VERSION "0.0.02"

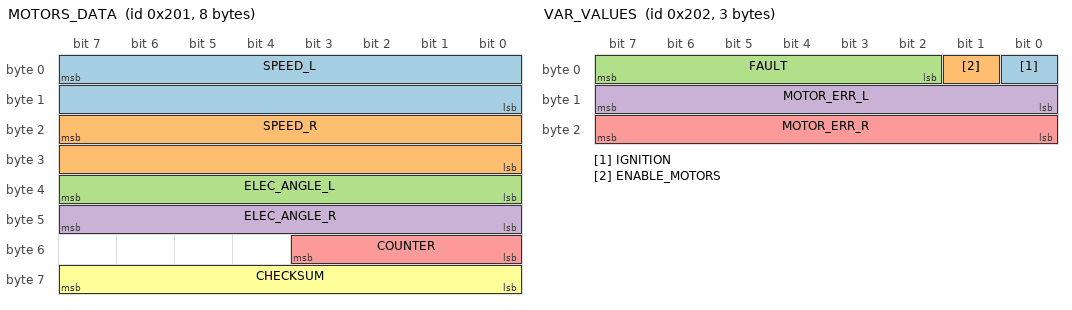
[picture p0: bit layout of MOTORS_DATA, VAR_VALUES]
BO_ 513 MOTORS_DATA: 8 XXX
  SG_ SPEED_L : 7|16@0- (1,0) [-1000|1000] "" XXX
  SG_ SPEED_R : 23|16@0- (1,0) [-1000|1000] "" XXX
  SG_ ELEC_ANGLE_L : 39|8@0+ (1,0) [0|0] "deprecated" XXX
  SG_ ELEC_ANGLE_R : 47|8@0+ (1,0) [0|0] "deprecated" XXX
  SG_ COUNTER : 51|4@0+ (1,0) [0|15] "" XXX
  SG_ CHECKSUM : 63|8@0+ (1,0) [0|255] "" XXX

BO_ 514 VAR_VALUES: 3 XXX
  SG_ IGNITION : 0|1@0+ (1,0) [0|1] "" XXX
  SG_ ENABLE_MOTORS : 1|1@0+ (1,0) [0|1] "" XXX
  SG_ FAULT : 7|6@0+ (1,0) [0|63] "" XXX
  SG_ MOTOR_ERR_L : 15|8@0+ (1,0) [0|255] "" XXX
  SG_ MOTOR_ERR_R : 23|8@0+ (1,0) [0|255] "" XXX

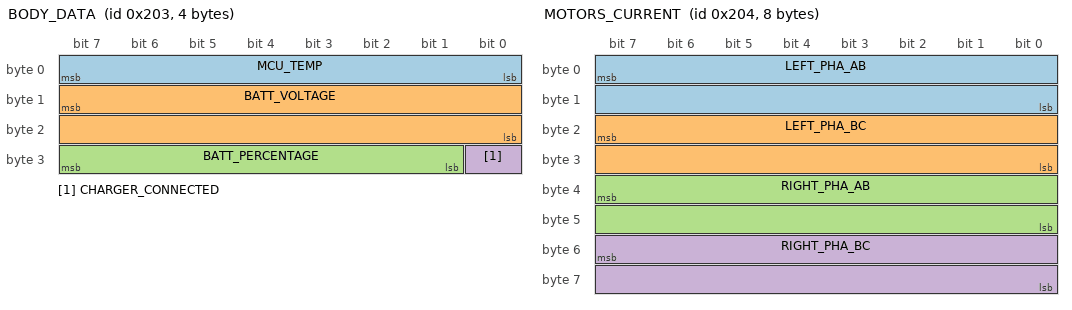
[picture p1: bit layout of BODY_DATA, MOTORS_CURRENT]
BO_ 515 BODY_DATA: 4 XXX
  SG_ MCU_TEMP : 7|8@0+ (0.1,0) [0|125] "" XXX
  SG_ BATT_VOLTAGE : 15|16@0+ (0.01,0) [0|60] "" XXX
  SG_ BATT_PERCENTAGE : 31|7@0+ (1,0) [0|100] "" XXX
  SG_ CHARGER_CONNECTED : 24|1@0+ (1,0) [0|1] "" XXX

BO_ 516 MOTORS_CURRENT: 8 XXX
  SG_ LEFT_PHA_AB : 7|16@0- (1,0) [-32768|32767] "" XXX
  SG_ LEFT_PHA_BC : 23|16@0- (1,0) [-32768|32767] "" XXX
  SG_ RIGHT_PHA_AB : 39|16@0- (1,0) [-32768|32767] "" XXX
  SG_ RIGHT_PHA_BC : 55|16@0- (1,0) [-32768|32767] "" XXX

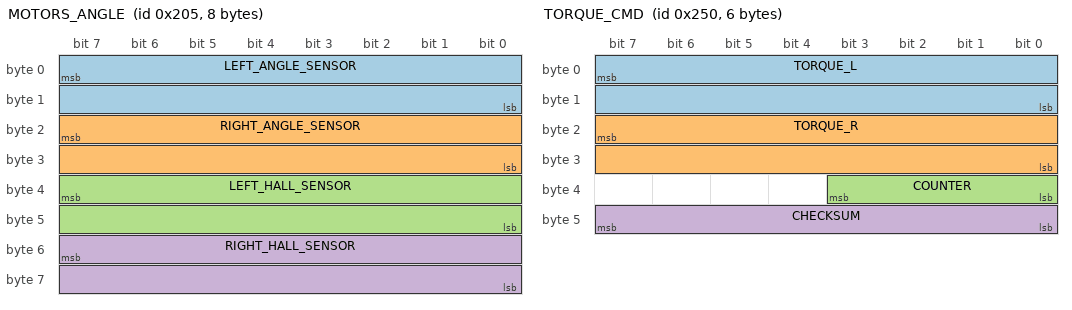
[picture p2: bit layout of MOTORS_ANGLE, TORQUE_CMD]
BO_ 517 MOTORS_ANGLE: 8 XXX
  SG_ LEFT_ANGLE_SENSOR : 7|16@0+ (1,0) [0|16384] "" XXX
  SG_ RIGHT_ANGLE_SENSOR : 23|16@0+ (1,0) [0|16384] "" XXX
  SG_ LEFT_HALL_SENSOR : 39|16@0+ (1,0) [0|360] "" XXX
  SG_ RIGHT_HALL_SENSOR : 55|16@0+ (1,0) [0|360] "" XXX

BO_ 592 TORQUE_CMD: 6 XXX
  SG_ TORQUE_L : 7|16@0- (1,0) [-1000|1000] "" XXX
  SG_ TORQUE_R : 23|16@0- (1,0) [-1000|1000] "" XXX
  SG_ COUNTER : 35|4@0+ (1,0) [0|15] "" XXX
  SG_ CHECKSUM : 47|8@0+ (1,0) [0|255] "" XXX

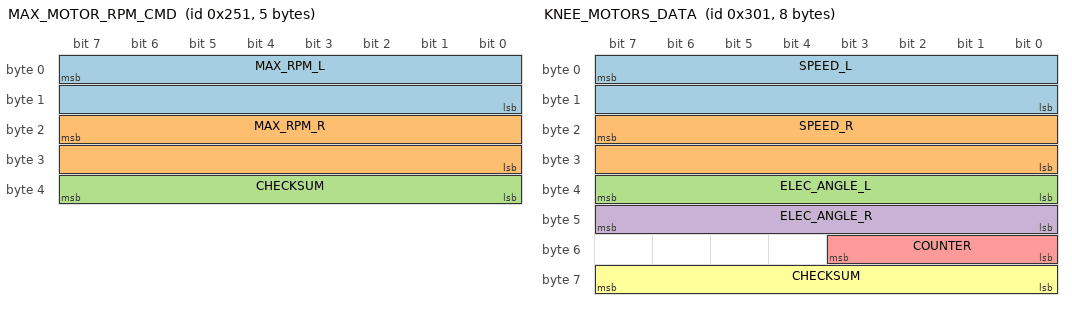
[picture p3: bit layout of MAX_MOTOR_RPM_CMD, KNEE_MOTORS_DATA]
BO_ 593 MAX_MOTOR_RPM_CMD: 5 XXX
  SG_ MAX_RPM_L : 7|16@0+ (1,0) [0|1000] "" XXX
  SG_ MAX_RPM_R : 23|16@0+ (1,0) [0|1000] "" XXX
  SG_ CHECKSUM : 39|8@0+ (1,0) [0|255] "" XXX

BO_ 769 KNEE_MOTORS_DATA: 8 XXX
  SG_ SPEED_L : 7|16@0- (1,0) [-1000|1000] "" XXX
  SG_ SPEED_R : 23|16@0- (1,0) [-1000|1000] "" XXX
  SG_ ELEC_ANGLE_L : 39|8@0+ (1,0) [0|0] "deprecated" XXX
  SG_ ELEC_ANGLE_R : 47|8@0+ (1,0) [0|0] "deprecated" XXX
  SG_ COUNTER : 51|4@0+ (1,0) [0|15] "" XXX
  SG_ CHECKSUM : 63|8@0+ (1,0) [0|255] "" XXX

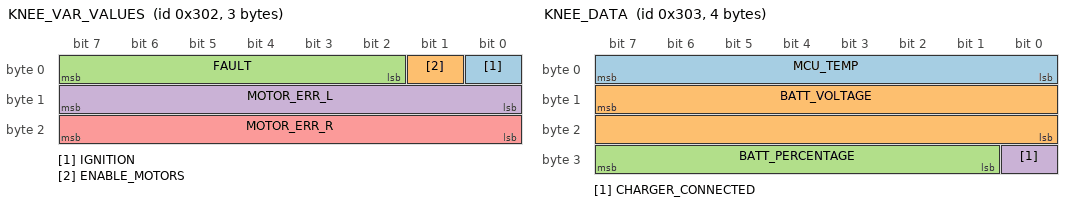
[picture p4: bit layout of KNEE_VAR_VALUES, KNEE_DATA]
BO_ 770 KNEE_VAR_VALUES: 3 XXX
  SG_ IGNITION : 0|1@0+ (1,0) [0|1] "" XXX
  SG_ ENABLE_MOTORS : 1|1@0+ (1,0) [0|1] "" XXX
  SG_ FAULT : 7|6@0+ (1,0) [0|63] "" XXX
  SG_ MOTOR_ERR_L : 15|8@0+ (1,0) [0|255] "" XXX
  SG_ MOTOR_ERR_R : 23|8@0+ (1,0) [0|255] "" XXX

BO_ 771 KNEE_DATA: 4 XXX
  SG_ MCU_TEMP : 7|8@0+ (0.1,0) [0|125] "" XXX
  SG_ BATT_VOLTAGE : 15|16@0+ (0.01,0) [0|60] "" XXX
  SG_ BATT_PERCENTAGE : 31|7@0+ (1,0) [0|100] "" XXX
  SG_ CHARGER_CONNECTED : 24|1@0+ (1,0) [0|1] "" XXX

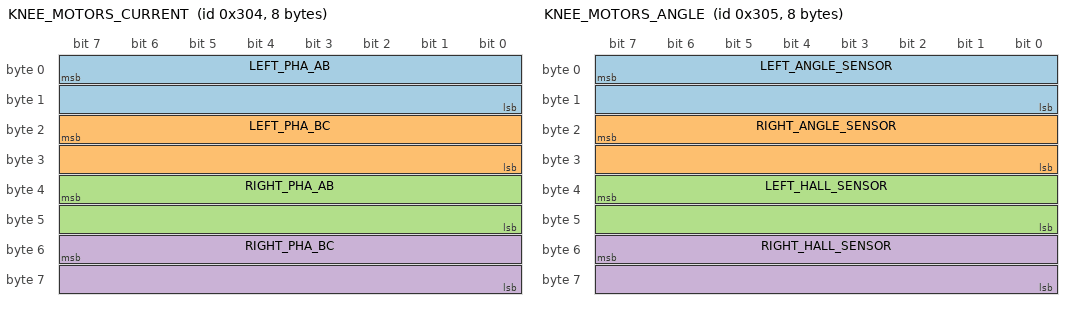
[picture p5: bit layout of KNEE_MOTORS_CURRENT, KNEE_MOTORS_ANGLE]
BO_ 772 KNEE_MOTORS_CURRENT: 8 XXX
  SG_ LEFT_PHA_AB : 7|16@0- (1,0) [-32768|32767] "" XXX
  SG_ LEFT_PHA_BC : 23|16@0- (1,0) [-32768|32767] "" XXX
  SG_ RIGHT_PHA_AB : 39|16@0- (1,0) [-32768|32767] "" XXX
  SG_ RIGHT_PHA_BC : 55|16@0- (1,0) [-32768|32767] "" XXX

BO_ 773 KNEE_MOTORS_ANGLE: 8 XXX
  SG_ LEFT_ANGLE_SENSOR : 7|16@0+ (1,0) [0|16384] "" XXX
  SG_ RIGHT_ANGLE_SENSOR : 23|16@0+ (1,0) [0|16384] "" XXX
  SG_ LEFT_HALL_SENSOR : 39|16@0+ (1,0) [0|360] "" XXX
  SG_ RIGHT_HALL_SENSOR : 55|16@0+ (1,0) [0|360] "" XXX

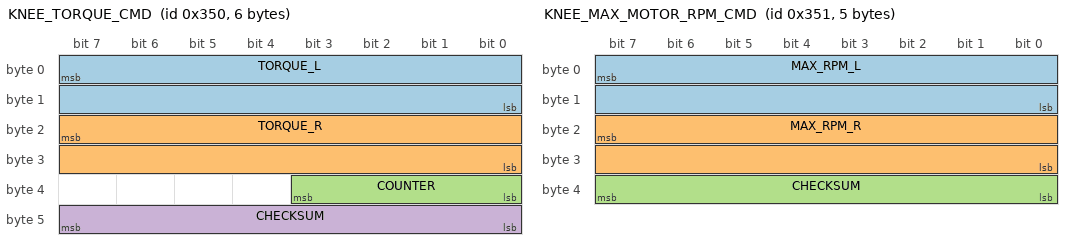
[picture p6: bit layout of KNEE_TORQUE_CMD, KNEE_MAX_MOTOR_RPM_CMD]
BO_ 848 KNEE_TORQUE_CMD: 6 XXX
  SG_ TORQUE_L : 7|16@0- (1,0) [-1000|1000] "" XXX
  SG_ TORQUE_R : 23|16@0- (1,0) [-1000|1000] "" XXX
  SG_ COUNTER : 35|4@0+ (1,0) [0|15] "" XXX
  SG_ CHECKSUM : 47|8@0+ (1,0) [0|255] "" XXX

BO_ 849 KNEE_MAX_MOTOR_RPM_CMD: 5 XXX
  SG_ MAX_RPM_L : 7|16@0+ (1,0) [0|1000] "" XXX
  SG_ MAX_RPM_R : 23|16@0+ (1,0) [0|1000] "" XXX
  SG_ CHECKSUM : 39|8@0+ (1,0) [0|255] "" XXX
